# pse84 register map
Vendor: Cypress Semiconductor; Series: PSE84; File version: 1.0
CPU: CM33 r0p1, little endian, MPU, FPU, VTOR, 3 interrupt priority bits
Registers are 32-bit, read-write, reset 0x0 unless marked. A register's access mark holds for its fields unless they carry their own. Offsets are from the block's base; [hi:lo] are bit positions; lines under a group give offsets from that group; {n}, {i} and the like mark numbered series; 'fields as' and 'values as' point back to an identical list; <NAME> marks a mode.

## I3C — I3C controller top
Base 0x42A50000
0x00 CORE group — registers in I3C IP core
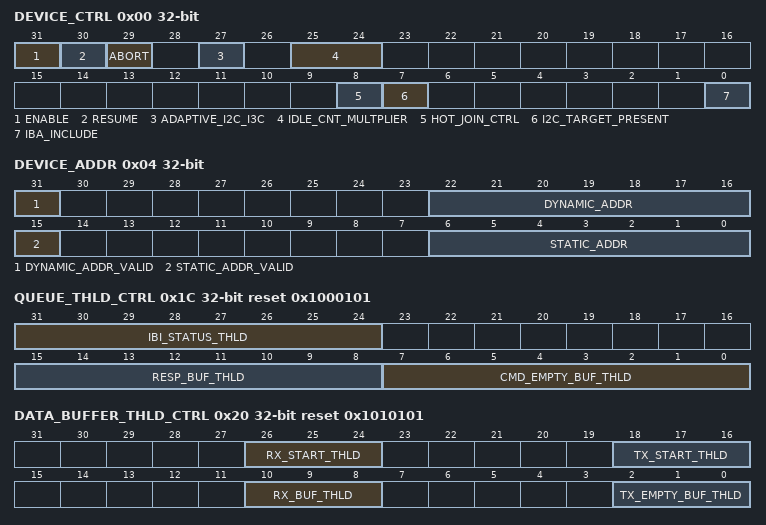
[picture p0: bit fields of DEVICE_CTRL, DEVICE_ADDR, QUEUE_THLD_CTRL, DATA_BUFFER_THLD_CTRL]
  0x00 DEVICE_CTRL — Device Control Register
    [31] ENABLE — I3C Enable Controls whether or not I3C functionality is enabled. When functioning as the Active Controller, software can write to this register to request to disable the I3C block. However, the block may not get disabled immediately and is 'Disabled' after commands in the Command queue (if any) are executed leading to a STOP condition on the bus and Controller FSM is in IDLE state (as indicated by PRESENT_STATE Register). When functioning as a Target, software can write to this register to request to disable the I3C block. However, the disable happens after the ongoing transfer is completed on the I3C bus. Software can read back 1'b0 from this field once disabling of I3C is completed. After power on reset, the software can enable I3C Secondary Controller or Target functionality by programming this bit to 1'b1. However the I3C bus interface of the block will respond to transfer on the bus, only after it observes Bus Available condition for BUS_AVAILABLE_TIME*IDLE_CNT_MULTPLIER counts of pclk period. The successful completion of Enable/Disable of the block depends on availability of SCL to the controller at the time of performing this operation, and hence may not happen instantly. Values: 0x0: Disables the I3C controller. 0x1: Enables the I3C controller.
    [30] RESUME — I3C Resume This bit is used to resume the I3C block after it goes to the Halt state. When functioning as the Active Controller, the block goes to the halt state (as indicated in PRESENT_STATE Register) due to any type of error in the transfer (the type of error is indicated by ERR_STATUS field in the RESPONSE_QUEUE_PORT register). After the block goes to the Halt state, the application has to write 1'b1 to this bit to resume. This bit is auto-cleared once the block resumes the transfers by initiating the next command. When functioning as a Target, the block goes to the halt state due to following conditions: 1 => Any type of error in the transfer (the type of error is indicated by ERR_STATUS field in the RESPONSE_QUEUE_PORT register) 2 => MRL Register updated by the Active Controller through SETMRL CCC. After the device has gone to halt state, the application has to take necessary action to handle the error condition and then write 1'b1 to this bit to resume the controller. This bit is auto-cleared once the controller is ready to accept new transfers.
    [29] ABORT — I3C Abort. This bit is only valid when this I3C Device is functioning as the Active Controller. This bit allows this device to relinquish the I3C Bus before completing the issued transfer. In response to an ABORT request, the Controller issues the STOP condition after the complete data byte is transferred or received. This bit is auto-cleared once the transfer is aborted and the controller issues a 'Transfer Abort' interrupt.
    [27] ADAPTIVE_I2C_I3C — Hot-Join Control for Adaptive I2C/I3C Mode This bit is only valid when this I3C Device is functioning as a Target and I3C_MODE_I2C.MODE_I2C is set to 0 (Adaptive I2C/I3C Mode). In Adaptive Mode, this bit is used to enable some features of this target device. This bit is cleared automatically if the controller determines the mode as I3C. Values: 0x0: The device initiates a Hot-Join without determining the bus mode and assuming itself to be on I3C bus. 0x1: The device initiates a Hot-Join request only after it has switched to I3C mode of operation.
    [25:24] IDLE_CNT_MULTPLIER — Idle count multiplier. This bit is only valid when this I3C Device is functioning as a Target. After power-on reset, this Target is enabled only after it sees both SDA and SCL lines idle for a specified time. This idle time is calculated by multipliying IDLE_CNT_MULTPLIER with BUS_AVAILABLE_TIME field in the BUS_FREE_AVAIL_TIMING register. Values: 0x00: BUS_AVAILABLE_TIME * 1 0x01: BUS_AVAILABLE_TIME * 2 0x10: BUS_AVAILABLE_TIME * 4 0x11: BUS_AVAILABLE_TIME * 8
    [8] HOT_JOIN_CTRL — Hot-Join ACK/NACK Control This bit is only valid when this I3C Device is functioning as the Active Controller. This bit acts as a global control to ACK/NACK the Hot-Join request from the devices. The Active Controller ACK/NACKs the Hot-Join request from other devices connected on the I3C Bus, based on programming of this bit. Values: 0x0: ACK the Hot-Join request. 0x1: NACK and send broadcast CCC(auto-disable) to disable Hot-join.
    [7] I2C_TARGET_PRESENT — I2C Target Present This bit is only valid when this I3C Device is functioning as the Active Controller. This bit indicates whether any Legacy I2C devices are present in the bus. In HDR mode, this field is used to select TSL over TSP in a mixed bus configuration. Values: 0x0 (DISABLED): I2C Target not present 0x1 (ENABLED): I2C Target present
    [0] IBA_INCLUDE — I3C Broadcast Address Include. This bit is only valid when this I3C Device is functioning as the Active Controller. This bit is used to include the I3C broadcast address (0x7E) in private transfers. Note: If the I3C broadcast address is not included in private transfers, In-band Interrupts (IBI) driven from Targets might not win address arbitration and IBIs will get delayed. Values: 0x0: I3C Broadcast Address is not included in Private Transfers 0x1: I3C Broadcast Address is included in Private Transfers
  0x04 DEVICE_ADDR — Device Address Register
    [31] DYNAMIC_ADDR_VALID — Dynamic Address Valid This bit is used to control whether the DYNAMIC_ADDR is valid or not. =>When functioning as the Primary Controller, the user/application must set this bit to 1 along with the DYNAMIC_ADDR. =>When functioning as a Target, the block sets this bit to 1 when the Active Controller assigns the Dynamic address during ENTDAA or SETDASA mechanism. + Values: 0x0: Dynamic Address is invalid 0x1: Dynamic Address is valid
    [22:16] DYNAMIC_ADDR — Device Dynamic Address. This field is used to program the Device Dynamic Address. The block uses this address for I3C transfers. => When functioning as the Primary Controller, the user/application must program the Dynamic Address. => When functioning as a Target, the Active Controller assigns this address during ENTDAA or SETDASA procedures.
    [15] STATIC_ADDR_VALID — Static Address Valid. This field is only valid when this I3C Device is functioning as a Target. Values: 0x0: Static Address in STATIC_ADDR field is invalid 0x1: Static Address in STATIC_ADDR field is valid
    [6:0] STATIC_ADDR — Device Static Address. This field is only valid when this I3C Device is functioning as a Target. The device uses this address to respond to SETDASA CCC Command to get the Dynamic Address if static address is valid (STATIC_ADDRESS_VALID must be set to 1).
  0x0C COMMAND_QUEUE_PORT wo reset not defined
    [31:0] COMMAND — 32-bit Command
  0x10 RESPONSE_QUEUE_PORT ro
    [31:0] RESPONSE — 32-bit Response
  0x14 TX_RX_DATA_PORT — Transmit/Receive Data Port Register
    [31:0] DATA_PORT — Transmit Data Port for write access and Receive Data Port for read access. This field is mapped to the TX Data Buffer when writing and to the RX Data Buffer when reading. The data is always packed in 4-byte aligned data words. If the command length is not aligned to the 4-bytes, then the additional data bytes have to be ignored.
  0x18 IBI_QUEUE_DATA ro — In-Band Interrupt Queue Data Register
    [31:0] IBI_DATA — In-Band Interrupt Data This register is mapped to the IBI Queue. The IBI Data is always packed in 4-byte aligned and put to the IBI Queue. If the incoming data is not aligned to the 4-bytes, then there are unused bytes in the end location of the IBI transfer.
  0x1C QUEUE_THLD_CTRL reset 0x1000101 — Queue Threshold Control Register
    [31:24] IBI_STATUS_THLD — In-Band Interrupt Status Threshold Value. This field controls the number of IBI status entries (or greater) in the IBI queue that trigger the IBI_THLD_STAT interrupt. Every In Band Interrupt received (with or without Payload) by the block generates an IBI status. The valid range is 0 to IC_IBI_BUF_DEPTH-1. The application should program only valid values. NOTE: The valid value is only 0 if IBI with payload is selected in the configuration. Values: 0x0 <= N < IC_RESP_BUF_DEPTH: Interrupt will trigger when queue has N+1 valid entries. Each IBI status entry can represent the complete (IBI payload byte size <= 4*IBI_DATA_THLD) IBI payload or a segment (IBI payload byte size > 4*IBI_DATA_THLD) of the IBI payload.
    [15:8] RESP_BUF_THLD — Response Buffer Threshold Value. Controls the minimum number of valid entries in the Response Queue that trigger the RESP_READY_STAT_INTR interrupt. The valid range is 0 to IC_RESP_BUF_DEPTH-1. The application should program only valid values. Values: 0x0 <= N < IC_RESP_BUF_DEPTH: Interrupt will trigger when queue has N+1 valid entries.
    [7:0] CMD_EMPTY_BUF_THLD — Command Buffer Empty Threshold Value Controls the minimum number of empty locations in the Command Queue that trigger the CMD_QUEUE_READY_STAT interrupt. The valid range is 0 to IC_CMD_BUF_DEPTH-1. The application should program only valid values. Values: 0x0: Interrupt will trigger when the queue is completely empty 0x0 < N < 16: Interrupt will trigger when queue has N empty locations.
  0x20 DATA_BUFFER_THLD_CTRL reset 0x1010101 — Data Buffer Threshold Control Register
    [26:24] RX_START_THLD — Receive Start Threshold Value. When functioning as the Active Controller, when the controller is set up to initiate a read transfer, it waits until either one of the conditions are met before it initiates the read transfer on the I3C Interface. => Data length (as specified in the command) number of locations are empty in the Receive FIFO. => Threshold number of locations (or more) are empty in the Receive FIFO. When functioning as a Target, the block ACKs a write request from the Active Controller only if threshold number of empty locations(or more) are available in its receive buffer. The supported values for RX_START_THLD are: 0x0: Threshold of at least 1 empty entry 0x1: Threshold of at least 4 empty entries 0x2: Threshold of at least 8 empty entries 0x3: Threshold of at least 16 empty entries 0x4: Threshold of at least 32 empty entries 0x5: Threshold of at least 64 empty entries
    [18:16] TX_START_THLD — Transfer Start Threshold Value. When functioning as the Active Controller, when the Controller is set up to initiate a write transfer, it waits until either one of the following conditions are met before it initiates the write transfer on the I3C Interface. => Data length (as specified in the command) number of locations are filled in the TX FIFO. => Threshold number of entries (or more) are available in the TX FIFO When functioning as a Target, the Target ACKs a read request from the Active Controller only if either one of the following conditions are met. => Data length (as specified in the command) number of locations are filled in the Transmit FIFO => Threshold number of entries (or more) are available in the Transmit FIFO Supported values: 0x0: Threshold of at least 1 valid entry 0x1: Threshold of at least 4 valid entries 0x2: Threshold of at least 8 valid entries 0x3: Threshold of at least 16 valid entries 0x4: Threshold of at least 32 valid entries 0x5: Threshold of at least 64 valid entries
    [10:8] RX_BUF_THLD — Receive Buffer Threshold Value. This field controls the number of valid entries (or above) in the RX FIFO that trigger the RX_THLD_STAT interrupt. If the programmed value is greater than the buffer depth, then threshold is set to IC_RX_BUF_DEPTH. Supported values: 0x0: Interrupt triggers with at least 1 valid entry 0x1: Interrupt triggers with at least 4 valid entries 0x2: Interrupt triggers with at least 8 valid entries 0x3: Interrupt triggers with at least 16 valid entries 0x4: Interrupt triggers with at least 32 valid entries 0x5: Interrupt triggers with at least 64 valid entries
    [2:0] TX_EMPTY_BUF_THLD — Transmit Buffer Empty Threshold Value This field controls the number of empty locations (or above) in the TX FIFO that trigger the TX_THLD_STAT interrupt. If the programmed value is greater than the buffer depth, then threshold is set to IC_TX_BUF_DEPTH. Supported values: 0x0: Interrupt triggers with at least 1 empty entry 0x1: Interrupt triggers with at least 4 empty entries 0x2: Interrupt triggers with at least 8 empty entries 0x3: Interrupt triggers with at least 16 empty entries 0x4: Interrupt triggers with at least 32 empty entries 0x5: Interrupt triggers with at least 64 empty entries
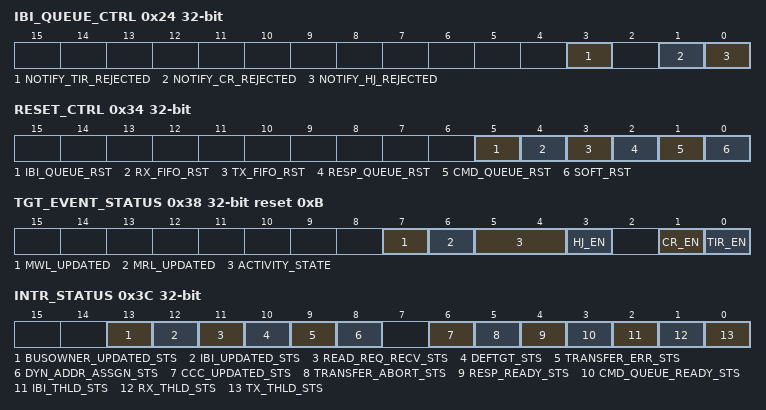
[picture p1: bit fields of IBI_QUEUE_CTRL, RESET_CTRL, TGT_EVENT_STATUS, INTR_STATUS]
  0x24 IBI_QUEUE_CTRL — IBI Queue Control Register
    [3] NOTIFY_TIR_REJECTED — Notify Rejected Target Interrupt Request Control. This bit is only valid when this I3C Device is functioning the Active Controller, and is used to suppress reporting to the application about rejected Target Interrupt Request. Values: 0x0: Disables passing the IBI Status to the IBI FIFO (hence not notifying the application) when a Target Interrupt Request is NACKed and auto-disabled based on the IBI_SIR_REQ_REJECT Register. 0x1: Enables writing the IBI Status to the IBI FIFO (hence notifying the application) when a Target Interrupt Request is NACKed and auto-disabled based on the IBI_SIR_REQ_REJECT Register.
    [1] NOTIFY_CR_REJECTED — Notify Rejected Controller Role Request (CR) Control. This bit is only valid when this I3C Device is functioning the Active Controller, and is used to suppress reporting to the application about Controller Role Request (CR) rejected. Values: 0x0: Disable passing the IBI Status to the IBI FIFO (hence not notifying the application) when a CR Request is NACKed and auto-disabled based on the IBI_CR_REQ_REJECT Register. 0x1: Enable writing the IBI Status to the IBI FIFO (hence notifying the application) when a CR Request is NACKed and auto-disabled based on the IBI_CR_REQ_REJECT Register.
    [0] NOTIFY_HJ_REJECTED — Notify Rejected Hot-Join Control. This bit is only valid when this I3C Device is functioning the Active Controller, and is used to suppress reporting to the application about Hot-Join request rejected (NACK and Auto Disable). Values: 0x0: Disable passing the IBI Status to the IBI FIFO (hence not notifying the application) when a HJ Request is NACKed and auto-disabled based on the DEVICE_CTRL.HOT_JOIN_CTRL. 0x1: Enable writing the IBI Status to the IBI FIFO (hence notifying the application) when a HJ Request is NACKed and auto-disabled based on the DEVICE_CTRL.HOT_JOIN_CTRL.
  0x2C IBI_CR_REQ_REJECT — IBI CR Request Rejection Control Register
    [31:0] CR_REQ_REJECT — Controller Role Request Reject. This field determines how the block responds to incoming Controller Role Requests from other Secondary Controller devices. The responses possible are: => ACK request to become Active Controller => NACK and send Directed DISEC CCC (with DISCR bit set) to disable the interrupting Controller. A device specific policy can be established by appropriately programming this register.
  0x30 IBI_TIR_REQ_REJECT — IBI TIR Request Rejection Control Register
    [31:0] SIR_REQ_REJECT — In-band Target Interrupt Request Reject. This field determines how the block responds to incoming Target Interrupt Requests from other Target devices. The responses possible are: => ACK request to become Active Controller => NACK and send Directed DISEC CCC (with DISINT bit set) to disable the interrupting Controller. A device specific policy can be established by appropriately programming this register.
  0x34 RESET_CTRL — Reset Control Register
    [5] IBI_QUEUE_RST — IBI Queue Software Reset. This bit is only valid when functioning as the Active Controller. Write 0x1 to this bit to exercise IBI Queue reset. This bit is cleared automatically once the IBI Queue reset is completed. Before the reset is completed, write accesses and read accesses to the other registers will return a bus error.
    [4] RX_FIFO_RST — Receive Buffer Software Reset. Write 0x1 to this bit to exercise Receive Buffer reset This bit is cleared automatically once the Receive buffer reset is completed. Before the reset is completed, write accesses and read accesses to the other registers will return a bus error.
    [3] TX_FIFO_RST — Transmit Buffer Software Reset. Write 0x1 to this bit to exercise Transmit Buffer reset. This bit is cleared automatically once the Transmit Buffer reset is completed. Before the reset is completed, write accesses and read accesses to the other registers will return a bus error.
    [2] RESP_QUEUE_RST — Response Queue Software Reset. Write 1'b1 to this bit to exercise Response Queue reset. This bit is cleared automatically once the Response Queue reset is completed. Before the reset is completed, write accesses and read accesses to the other registers will return a bus error.
    [1] CMD_QUEUE_RST — Command Queue Software Reset. Write 0x1 to this bit to exercise Command Queue reset. This bit is cleared automatically once the Command Queue reset is completed. Before the reset is completed, write accesses and read accesses to the other registers will return a bus error.
    [0] SOFT_RST — Core Software Reset. Write 1'b1 to this bit to exercise software reset. This resets all Buffers - Receive, Transmit, Command, and Response. This bit is cleared automatically once the core reset is completed. Before the reset is completed, write accesses and read accesses to the other registers will return a bus error. To finish the reset, it can take up to (15*Tpclk + 22*Tcore_clk) in worst case. (below reset cases are similar).
  0x38 TGT_EVENT_STATUS reset 0xB — Target Event Status Register
    [7] MWL_UPDATED — MWL Updated Status. This bit indicates a SETMWL CCC is received by the Target. The updated MWL value can be read from TGT_MAX_LEN register. This status can be cleared by writing 0x1 to this field after reading the updated MWL.
    [6] MRL_UPDATED — MRL Updated Status. This bit indicates a SETMRL CCC is received by the Target. The updated MRL value can be read from TGT_MAX_LEN register. This status can be cleared by writing 0x1 to this field after reading the updated MRL.
    [5:4] ACTIVITY_STATE ro — Activity State Status This bit reflects the Activity State of this Target set by the Active Controller. Values: 0x0: ENTAS0 0x1: ENTAS1 0x2: ENTAS2 0x3: ENTAS3
    [3] HJ_EN — Hot-Join Interrupt Enable. This bit is only valid when this I3C Device is functioning as a Target, and reflects whether the Hot-Join Request Interrupts are allowed on the I3C bus or not. The Target application can choose to Disable HJ Capability of the Target controller (if selected) by setting this field to 0 before 'Enabling' the block. When done so, the Target will not initiate Hot Join and will take part in Address Assignment without initiating Hot Join. If this field is NOT set to 0 by the Target application, it can be set or cleared by the I3C Controller via ENEC or DISEC CCCs. Once Disabled by software, CCCs do not have any effect on this field.
    [1] CR_EN ro — Controller Role Request (CR) Enable. This bit is only valid when this I3C Device is functioning as a Target, and reflects whether the controller can initiate the Controller Role Request (CR) on the I3C bus or not. Usually, this bit is set or cleared by the Active Controller through ENEC or DISEC CCC.
    [0] TIR_EN ro — Target Interrupt Request Enable. This bit is only valid when this I3C Device is functioning as a Target, and reflects whether the block can initiate the SIR on the I3C bus or not. Usually, this bit is set or cleared by the Active Controller through ENEC or DISEC CCC.
  0x3C INTR_STATUS — Interrupt Status Register
    [13] BUSOWNER_UPDATED_STS — This interrupt is set when the block changes from being the Active Controller to a Secondary Controller/Target or vice versa. This bit can be cleared by writing 0x1.
    [12] IBI_UPDATED_STS — IBI status is updated. This field is used only When functioning as a Target. It indicates that the IBI request initiated through SIR request register is addressed and status is updated.
    [11] READ_REQ_RECV_STS — Read Request Received. This field is used only when functioning as a Target. Read Request received from the Active Controller when CMDQ is empty. This bit can be cleared by writing 0x1.
    [10] DEFTGT_STS — Define Target CCC Received Status. This interrupt is generated if DEFTGTS CCC is received. This bit can be cleared by writing 0x1.
    [9] TRANSFER_ERR_STS — Transfer Error Status. This interrupt is generated if any error occurs during transfer. The error type is specified in the response packet associated with the command (in ERR_STATUS field of RESPONSE_QUEUE_PORT register). This bit can be cleared by writing 0x1.
    [8] DYN_ADDR_ASSGN_STS — Dynamic Address Assigned Status. This field is used only When functioning as a Target,. This interrupt is generated if the device's Dynamic Address is assigned through SETDASA or ENTDAA CCC. This bit can be cleared by writing 0x1.
    [6] CCC_UPDATED_STS — CCC Table Updated Status. This field is used only when functioning as a Target. This interrupt is generated if any of the CCC registers are updated by the I3C Controller through CCC commands. This interrupt can be cleared by writing 0x1.
    [5] TRANSFER_ABORT_STS — Transfer Abort Status. This field is used only when functioning as the Active Controller,. This interrupt is generated if the transfer is aborted. This interrupt can be cleared by writing 0x1.
    [4] RESP_READY_STS ro — Response Queue Ready Status. This interrupt is generated when number of entries in the response queue is greater than or equal to the threshold value specified by the RESP_BUF_THLD field in the QUEUE_THLD_CTRL register. This interrupt is cleared automatically when the number of entries in the response buffer is less than the threshold value specified.
    [3] CMD_QUEUE_READY_STS ro — Command Queue Ready. This interrupt is generated when number of empty locations in the command queue is greater than or equal to the threshold value specified by the CMD_EMPTY_BUF_THLD field in the QUEUE_THLD_CTRL register. This interrupt is cleared automatically when the number of empty locations in the command buffer is less than the threshold value specified.
    [2] IBI_THLD_STS ro — IBI Buffer Threshold Status. This field is only used when the block is functioning as the Active Controller. This interrupt is generated when the number of entries in the IBI buffer is greater than or equal to the threshold value specified by the IBI_BUF_THLD field in the QUEUE_THLD_CTRL register. This interrupt is cleared automatically when the number of entries in IBI buffer is less than the threshold value specified.
    [1] RX_THLD_STS ro — Receive Buffer Threshold Status. This interrupt is generated when number of entries in the receive buffer is greater than or equal to threshold value specified by the RX_BUF_THLD field in the DATA_BUFFER_THLD_CTRL register. This interrupt is cleared automatically when the number of entries in receive buffer is less than the threshold value specified.
    [0] TX_THLD_STS ro — Transmit Buffer Threshold Status. This interrupt is generated when the number of empty locations in the transmit buffer is greater than or equal to the threshold value specified by the TX_EMPTY_BUF_THLD field in the DATA_BUFFER_THLD_CTRL register. This interrupt is cleared automatically when the number of empty locations in transmit buffer is less than threshold value specified.
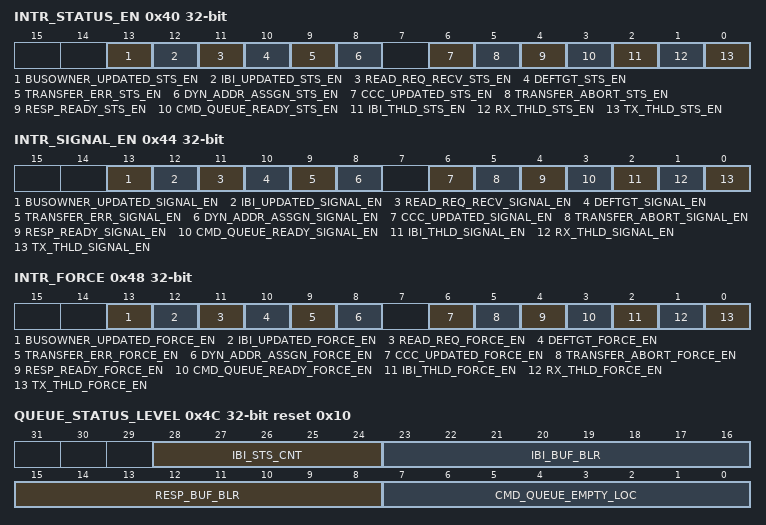
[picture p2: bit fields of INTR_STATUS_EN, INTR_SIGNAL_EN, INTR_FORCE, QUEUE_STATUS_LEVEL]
  0x40 INTR_STATUS_EN — Interrupt Status Enable Register.
    [13] BUSOWNER_UPDATED_STS_EN — Bus owner Updated Status Enable
    [12] IBI_UPDATED_STS_EN — IBI Updated Status Enable This field is only valid when functioning as a Target.
    [11] READ_REQ_RECV_STS_EN — Read Request Received Status Enable This field is only valid when functioning as a Target.
    [10] DEFTGT_STS_EN — Define Target CCC Received Status Enable
    [9] TRANSFER_ERR_STS_EN — Transfer Error Status Enable
    [8] DYN_ADDR_ASSGN_STS_EN — Dynamic Address Assigned Status Enable This field is only valid when functioning as a Target.
    [6] CCC_UPDATED_STS_EN — CCC Table Updated Status Enable. This field is only valid when functioning as a Target.
    [5] TRANSFER_ABORT_STS_EN — Transfer Abort Status Enable. This field is only valid when functioning as the Active Controller.
    [4] RESP_READY_STS_EN — Response Queue Ready Status Enable
    [3] CMD_QUEUE_READY_STS_EN — Command Queue Ready Status Enable
    [2] IBI_THLD_STS_EN — IBI Buffer Threshold Status Enable This field is only valid when functioning aa the Active Controller.
    [1] RX_THLD_STS_EN — Receive Buffer Threshold Status Enable
    [0] TX_THLD_STS_EN — Transmit Buffer Threshold Status Enable
  0x44 INTR_SIGNAL_EN — Interrupt Signal Enable Register
    [13] BUSOWNER_UPDATED_SIGNAL_EN — Bus owner Updated Signal Enable
    [12] IBI_UPDATED_SIGNAL_EN — IBI Updated Signal Enable This field is only valid when functioning as a Target.
    [11] READ_REQ_RECV_SIGNAL_EN — Read Request Received Signal Enable This field is only valid when functioning as a Target.
    [10] DEFTGT_SIGNAL_EN — Define Target CCC Received Signal Enable
    [9] TRANSFER_ERR_SIGNAL_EN — Transfer Error Signal Enable
    [8] DYN_ADDR_ASSGN_SIGNAL_EN — Dynamic Address Assigned Signal Enable This field is only valid when functioning as a Target.
    [6] CCC_UPDATED_SIGNAL_EN — CCC Table Updated Signal Enable. This field is only valid when functioning as a Target.
    [5] TRANSFER_ABORT_SIGNAL_EN — Transfer Abort Signal Enable. This field is only valid when functioning as the Active Controller.
    [4] RESP_READY_SIGNAL_EN — Response Queue Ready Signal Enable
    [3] CMD_QUEUE_READY_SIGNAL_EN — Command Queue Ready Signal Enable
    [2] IBI_THLD_SIGNAL_EN — IBI Buffer Threshold Signal Enable This field is only valid when functioning aa the Active Controller.
    [1] RX_THLD_SIGNAL_EN — Receive Buffer Threshold Signal Enable
    [0] TX_THLD_SIGNAL_EN — Transmit Buffer Threshold Signal Enable
  0x48 INTR_FORCE wo — Interrupt Force Enable Register
    [13] BUSOWNER_UPDATED_FORCE_EN — Bus owner Updated Force Enable
    [12] IBI_UPDATED_FORCE_EN — IBI Updated Force Enable This field is only valid when functioning as a Target.
    [11] READ_REQ_FORCE_EN — Read Request Received Force Enable This field is only valid when functioning as a Target.
    [10] DEFTGT_FORCE_EN — Define Target CCC Received Force Enable
    [9] TRANSFER_ERR_FORCE_EN — Transfer Error Force Enable
    [8] DYN_ADDR_ASSGN_FORCE_EN — Dynamic Address Assigned Force Enable This field is only valid when functioning as a Target.
    [6] CCC_UPDATED_FORCE_EN — CCC Table Updated Force Enable. This field is only valid when functioning as a Target.
    [5] TRANSFER_ABORT_FORCE_EN — Transfer Abort Force Enable. This field is only valid when functioning as the Active Controller.
    [4] RESP_READY_FORCE_EN — Response Queue Ready Force Enable
    [3] CMD_QUEUE_READY_FORCE_EN — Command Queue Ready Force Enable
    [2] IBI_THLD_FORCE_EN — IBI Buffer Threshold Force Enable This field is only valid when functioning aa the Active Controller.
    [1] RX_THLD_FORCE_EN — Receive Buffer Threshold Force Enable
    [0] TX_THLD_FORCE_EN — Transmit Buffer Threshold Force Enable
  0x4C QUEUE_STATUS_LEVEL ro reset 0x10
    [28:24] IBI_STS_CNT
    [23:16] IBI_BUF_BLR — IBI Buffer Level Value. This field is used when functioning as the Active Controller. When IC_HAS_IBI_DATA = 0, contains ontains the number of Valid IBI Status entries in the IBI Buffer. When IC_HAS_IBI_DATA = 1, contains the number of valid IBI Data entries in the IBI Data Buffer.
    [15:8] RESP_BUF_BLR — Response Buffer Level Value. Contains the number of valid data entries in the response Buffer.
    [7:0] CMD_QUEUE_EMPTY_LOC — Command Queue Empty Locations. Contains the number of empty locations in the command Buffer.
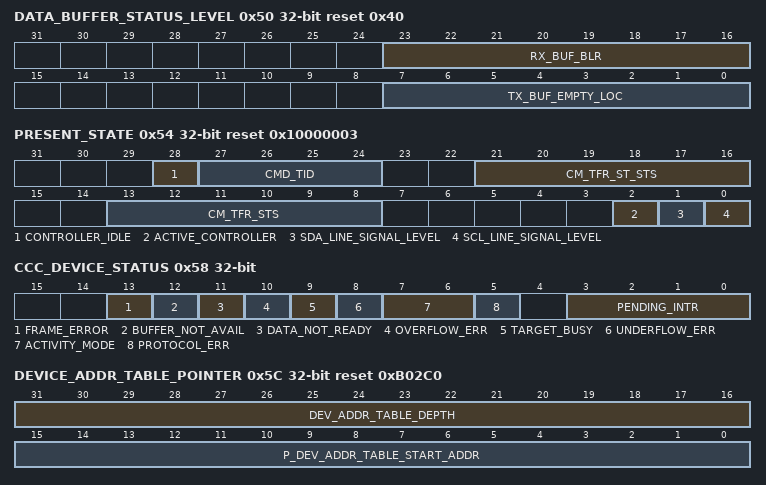
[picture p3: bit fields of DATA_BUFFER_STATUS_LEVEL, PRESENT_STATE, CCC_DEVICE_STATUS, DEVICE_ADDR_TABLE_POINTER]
  0x50 DATA_BUFFER_STATUS_LEVEL ro reset 0x40
    [23:16] RX_BUF_BLR — Receive Buffer Level Value. Contains the number of valid data entries in the receive Buffer.
    [7:0] TX_BUF_EMPTY_LOC — Transmit Buffer Empty Level Value. Contains the number of empty locations in the transmit Buffer.
  0x54 PRESENT_STATE ro reset 0x10000003
    [28] CONTROLLER_IDLE — This bit is only valid when this I3C Device is functioning the Active Controller, and reflects whether the block is in the Idle state or not. This bit is set when all the Queues (Command , Response, IBI) and Buffers (Transmit and Receive) are empty and the Controller State machine is in Idle state. Values: 0x0 Controller is not in IDLE State 0x1 Controller is in IDLE State.
    [27:24] CMD_TID — This field reflects the Transaction-ID of the current executing command.
    [21:16] CM_TFR_ST_STS — Active Controller Transfer State Status. This bit is only valid when this I3C Device is functioning the Active Controller, and indicates the state of current transfer currently executing by the I3C block. Values: 0x0: IDLE (Controller is Idle state, waiting for commands from application or Target initated In-band Interrupt) 0x1: START Generation State. 0x2: RESTART Generation State. 0x3: STOP Generation State. 0x4: START Hold Generation for the Target Initiated START State. 0x5: Broadcast Write Address Header(7'h7E,W) Generation State. 0x6: Broadcast Read Address Header(7'h7E,R) Generation State. 0x7: Dynamic Address Assignment State. 0x8: Target Address Generation State. 0xB: CCC Byte Generation State. 0xC: HDR Command Generation State. 0xD: Write Data Transfer State. 0xE: Read Data Transfer State. 0xF: In-Band Interrupt(SIR) Read Data State. 0x10: In-Band Interrupt Auto-Disable State 0x11: HDR-DDR CRC Data Generation/Receive State. 0x12: Clock Extension State. 0x13: Halt State.
    [13:8] CM_TFR_STS — Transfer Type Status. Indicates the type of transfer currently executing by the I3C block. When functioning as the Active Controller, possible values are: 0x0: IDLE (Block is in Idle state, waiting for commands from application or Target initated In-band Interrupt) 0x1: Broadcast CCC Write Transfer. 0x2: Directed CCC Write Transfer. 0x3: Directed CCC Read Transfer. 0x4: ENTDAA Address Assignment Transfer. 0x5: SETDASA Address Assignment Transfer. 0x6: Private I3C SDR Write Transfer. 0x7: Private I3C SDR Read Transfer. 0x8: Private I2C SDR Write Transfer. 0x9: Private I2C SDR Read Transfer. 0xA: Private HDR Ternary Symbol (TS) Write Transfer. 0xB: Private HDR Ternary Symbol (TS) Read Transfer. 0xC: Private HDR Double-Data Rate (DDR) Write Transfer. 0xD: Private HDR Double-Data Rate (DDR) Read Transfer. 0xE: Servicing In-Band Interrupt Transfer. 0xF: Halt state (Block is in Halt State, waiting for the application to resume through DEVICE_CTRL Register) When functioning as a Target, possible values are: 0x0: IDLE (Block is in Idle state) 0x1: Hot-Join transfer state 0x2: IBI transfer state 0x3: Controller write transfer ongoing 0x4: Read data prefetch state 0x5: Controller read transfer ongoing 0x6: Bock is controller in Halt State waiting for resume from application
    [2] ACTIVE_CONTROLLER — This Bit is used to check whether the block is currently the Active Controller or not. The Active Controller is the Controller that owns the SCL line. Values: 0x0: Secondary Controller is not the Active Controller and needs to request to be the Active Controller before initiating any transfer on the line. 0x1: Secondary Controller is the Active Controller and can initiate transfers on the line.
    [1] SDA_LINE_SIGNAL_LEVEL — This bit is only valid when this I3C Device is functioning the Active Controller, and is used for debug and error recovery. This bit reflects the value of the synchronized sda_in_a signal.
    [0] SCL_LINE_SIGNAL_LEVEL — This bit is only valid when this I3C Device is functioning the Active Controller, and is used for debug and error recovery. This bit reflects the value of the synchronized scl_in_a signal.
  0x58 CCC_DEVICE_STATUS ro — Device Operating Status Register.
    [13] FRAME_ERROR — Frame Error This bit is only valid when this I3C Device is functioning as a Target, and is set when a private write request initiated by the Active Controller has a frame error in HDR-DDR/HDR-TSP/TSL mode. This is cleared only after the Active Controller reads the device status through GETSTATUS_CCC.
    [12] BUFFER_NOT_AVAIL — Buffer not available This bit is only valid when this I3C Device is functioning as a Target, and is set when a private write request initiated by the Active Controller is NACKED because of RX buffer not having RX_BUF_THLD number of empty locations or Response buffer being full. In SDR mode of operation this is cleared when the Active Controller issues GETSTATUS CCC or upon space becoming available in the buffer and the successful completion of the next write transfer. In HDR mode of operation it is cleared only when the Active Controller issues GETSTATUS CCC.
    [11] DATA_NOT_READY — Data not ready This bit is only valid when this I3C Device is functioning as a Target, and is set when private a private read request initiated by the Active Controller is NACKED because of any of the following conditions Command FIFO Empty. Transmit FIFO threshold is not met. Response FIFO Full. This bit is cleared when the Active Controller issues GETSTATUS CCC or upon successful completion of the subsequent read transfer.
    [10] OVERFLOW_ERR — Overflow Error This bit is only valid when this I3C Device is functioning as a Target, and is set when an overflow error condition is detected during a private write transfer initiated by the Active Controller. This is cleared only after the Active Controller reads the Device Status through GETSTATUS CCC.
    [9] TARGET_BUSY — Target Busy This bit is set if any change is made by the Active Controller to the MRL register or occurance of any error. It is cleared after Target application resumes the block operation by writing to the RESUME bit of the DEVICE_CONTROL register.
    [8] UNDERFLOW_ERR — Underflow error This bit is only valid when this I3C Device is functioning as a Target, and is set when terminates a private read transfer initiated by the Active Controller is terminated by the device because of unavailability of data in the transmit buffer. This bit is cleared only after the Active Controller reads the Device Status through a GETSTATUS CCC.
    [7:6] ACTIVITY_MODE — Pending Interrupt This field reflects the value from I3C.CCC_GETSTATUS.ACT_MODE.
    [5] PROTOCOL_ERR — Protocol Error This bit is only valid when this I3C Device is functioning as a Target, and is set when a Parity/CRC error is encountered during a private write transfer initiated by the Active Controller.
    [3:0] PENDING_INTR — Pending Interrupt This field reflects the value from I3C.CCC_GETSTATUS.PENDING_INT.
  0x5C DEVICE_ADDR_TABLE_POINTER ro reset 0xB02C0 — Pointer for Device Address Table
    [31:16] DEV_ADDR_TABLE_DEPTH — Depth of the Device Address Table in the internal memory.
    [15:0] P_DEV_ADDR_TABLE_START_ADDR — Start Address of the Device Address Table in the internal memory.
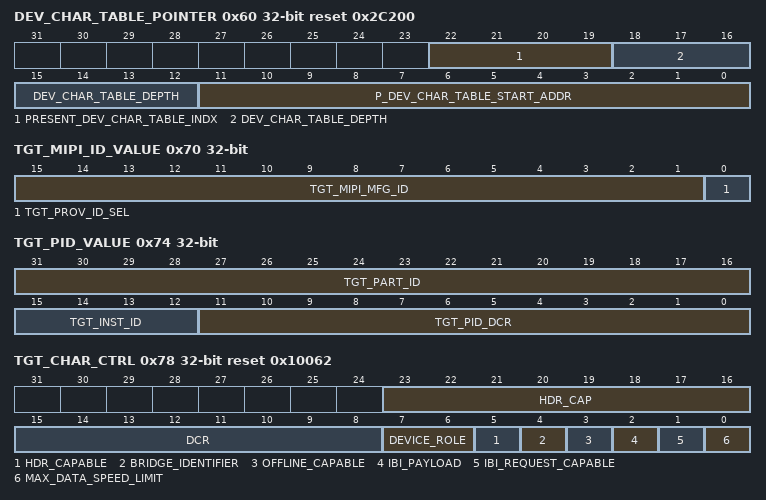
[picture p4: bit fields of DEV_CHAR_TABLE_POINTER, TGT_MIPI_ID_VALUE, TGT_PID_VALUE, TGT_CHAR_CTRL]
  0x60 DEV_CHAR_TABLE_POINTER reset 0x2C200 — Pointer for Device Characteristics Table
    [22:19] PRESENT_DEV_CHAR_TABLE_INDX — Current index of the Device Characteristics Table. This field returns the current location of Device Characteristics Table index. Initially, this index points to 0. Once the complete characteristics information of a Target device is written into Device Characteristics Table during ENTDAA, this index increments by 1. The first winning device information is stored in Device Characteristics Table index 0, the second winning device information in index 1, and so on. If required, this index can be used to override the location, where characteristic information of Target devices on the I3C bus are written during ENTDAA. Hence, this field is useful only when the device is functioning as the Active Controller. During DEFTGTS CCC, the index always starts from 0. When the device is functioning as a Target, this field is read-only.
    [18:12] DEV_CHAR_TABLE_DEPTH ro — Depth of Device Characteristics Table in the internal memory.
    [11:0] P_DEV_CHAR_TABLE_START_ADDR ro — Start Address of the Device Characteristics Table in the internal memory.
  0x6C VENDOR_SPECIFIC_REG_POINTER ro reset 0xB0 — Pointer for Vendor Specific Registers.
    [15:0] P_VENDOR_REG_START_ADDR — Start Address of Vendor specific registers.
  0x70 TGT_MIPI_ID_VALUE — I3C MIPI Manufacturer ID Register
    [15:1] TGT_MIPI_MFG_ID — Specifies the MIPI Manufacturer ID (Provisioned ID [47:33]).
    [0] TGT_PROV_ID_SEL — Specifies the Provisioned ID Type Selector (Provisioned ID [32]). Values: 0x0: Vendor Fixed Value 0x1: Random Value
  0x74 TGT_PID_VALUE — I3C Normal Provisional ID Register
    [31:16] TGT_PART_ID — Specifies the Part ID of this I3C block (PID[31:16]).
    [15:12] TGT_INST_ID — Specifies the MIPI Instance ID of this I3C block (Provisioned ID [15:12]).
    [11:0] TGT_PID_DCR — Specifies the last 12 bit of the MIPI Provisioned ID of this I3C block (Provisioned ID [11:0]).
  0x78 TGT_CHAR_CTRL reset 0x10062 — I3C Target Characteristic Register.
    [23:16] HDR_CAP ro
    [15:8] DCR — I3C Device Characteristic Regster (DCR) Value
    [7:6] DEVICE_ROLE — Device Role field in Bus Characteristic Register (BCR[7:6]). This field is set to 1 by default if configuration parameter IC_DEVICE_ROLE is set to 0x3 (Secondary Controller). The application is not expected to change the role once configured. But if the application chooses to operate the Secondary Controller (IC_DEVICE_ROLE==3) as 'Target Only' through programming, then the Device Role can be overwritten as Target (BCR[7:6] = 0x0). The field is Reset to its default value upon HW/SW Reset. SW must program the values again after issuing reset.
    [5] HDR_CAPABLE — SDR Only or SDR and HDR Capable field in Bus Characteristic Register (BCR[5]). This bit is set if any of the configuration parameter IC_SPEED_HDR_TS or IC_SPEED_HDR_DDR is set to 1. It is to be noted that the programming this field to 0 does not Disable the HDR Feature itself. This bit can be modified by the application if it does not want to advertise the Target's HDR capability to the Active Controller. The field is Reset to its default value upon HW/SW Reset. SW must program the values again after issuing reset.
    [4] BRIDGE_IDENTIFIER ro — Bridge Identifier field in Bus Characteristic Register (BCR[4]). This bit is set if configuration parameter IC_SLV_BRIDGE is set to 1.
    [3] OFFLINE_CAPABLE ro — Offline Capable field in Bus Characteristic Register (BCR[3]). This bit is set if configuration parameter IC_SLV_OFFLINE_CAP is set to 1.
    [2] IBI_PAYLOAD ro — IBI Payload field in Bus Characteristic Register (BCR[2]). This bit is set if configuration parameter IC_SLV_IBI_DATA is set to 1.
    [1] IBI_REQUEST_CAPABLE ro — IBI Request Capable field in Bus Characteristic Register (BCR[1]). This bit is set if configuration parameter IC_SLV_IBI is set to 1.
    [0] MAX_DATA_SPEED_LIMIT — Max Data Speed Limitation field in Bus Characteristic Register (BCR[0]). Specifies whether or not this I3C device has a maximum data speed limitation. If this bit is set to 0, controller NACK's the GETMXDS CCC sent by the Active Controller. If this bit is set to 1, controller returns the data in MAX_DATA_SPEED and MAX_READ_TURNAROUND register in response the GETMXDS CCC sent by the Active Controller. The field is reset to its default value upon HW/SW Reset. SW must program the values again after issuing reset.
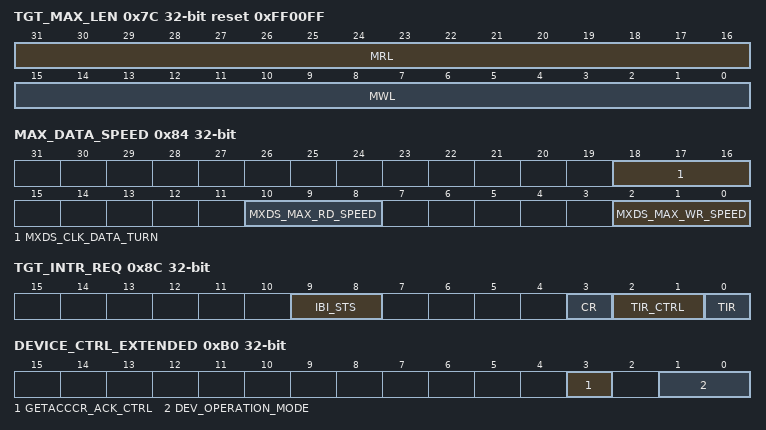
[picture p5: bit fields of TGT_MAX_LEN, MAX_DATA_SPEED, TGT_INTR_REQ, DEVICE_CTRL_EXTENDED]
  0x7C TGT_MAX_LEN ro reset 0xFF00FF — I3C Max Write/Read Length Register.
    [31:16] MRL — I3C Device Max Read Length
    [15:0] MWL — I3C Device Max Write Length
  0x80 MAX_READ_TURNAROUND ro — MXDS Maximum Read Turnaround Time.
    [23:0] MXDS_MAX_RD_TURN — Specifies the maximum read turnaround time (in microseconds (us)) of this I3C device.
  0x84 MAX_DATA_SPEED ro — Maximum Data Speed Register
    [18:16] MXDS_CLK_DATA_TURN, [10:8] MXDS_MAX_RD_SPEED, [2:0] MXDS_MAX_WR_SPEED
  0x8C TGT_INTR_REQ — Target Interrupt Request Register
    [9:8] IBI_STS ro
    [3] CR
    [2:1] TIR_CTRL
    [0] TIR — Target Interrupt Request When set, the Target Controller attempts to issue the SIR on the I3C bus. Once issued and when the Active Controller accepts (ACK), or if the block is unable to issue the SIR, then the block clears this bit automatically and updates the IBI_STS field. If the NACK response is received for the SIR, the block reattempts the SIR upon detecting the next START condition from the Active Controller or after the Bus Available Time. Once set, the application cannot clear this bit.
  0xB0 DEVICE_CTRL_EXTENDED — Device Control Extended Register
    [3] GETACCCR_ACK_CTRL — When functioning as a Target, this bit determines whether GETACCCR CCC from the Active Controller will be ACKed or NACKed. Values: 0x0: ACK the GETACCCR CCCs 0x1: NACK the GETACCCR CCCs
    [1:0] DEV_OPERATION_MODE — This bit is used to select the initial device role before the block is enabled. This field should only be written before the I3C block is enabled This field is automatically updated by the block once the a role change takes place. Values: 0x0: Primary Controller (starts as the Active Controller and initializes/configures the I3C bus) 0x1: Secondary Controller (starts as a Target, but can become the Active Controller)
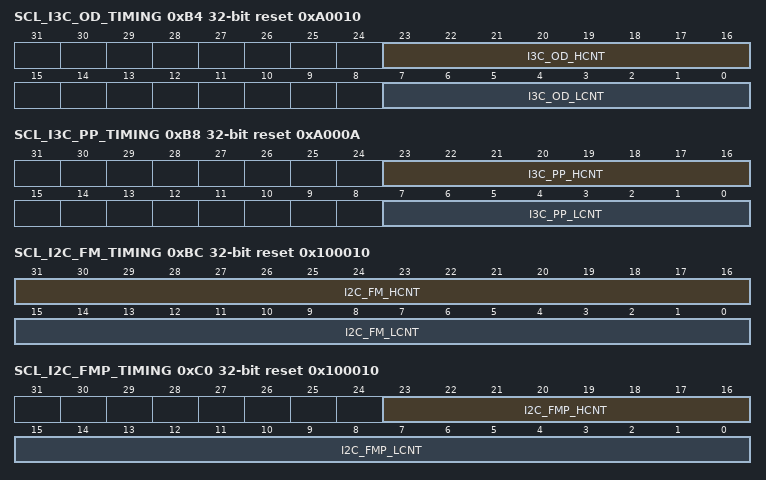
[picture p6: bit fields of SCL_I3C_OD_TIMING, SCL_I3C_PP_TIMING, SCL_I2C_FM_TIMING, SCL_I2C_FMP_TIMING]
  0xB4 SCL_I3C_OD_TIMING reset 0xA0010 — SCL I3C Open Drain Timing Register
    [23:16] I3C_OD_HCNT — I3C Open Drain High Count. SCL open-drain High count (I3C) for I3C transfers targeted to I3C devices.
    [7:0] I3C_OD_LCNT — I3C Open Drain Low Count. SCL Open-drain low count for I3C transfers targeted to I3C devices.
  0xB8 SCL_I3C_PP_TIMING reset 0xA000A — SCL I3C Push Pull Timing Register
    [23:16] I3C_PP_HCNT — I3C Push Pull High Count. SCL push-pull High count for I3C transfers targeted to I3C devices.
    [7:0] I3C_PP_LCNT — I3C Push Pull Low Count. SCL Push-pull low count for I3C transfers targeted to I3C devices.
  0xBC SCL_I2C_FM_TIMING reset 0x100010 — SCL I2C Fast Mode Timing Register
    [31:16] I2C_FM_HCNT — I2C Fast Mode High Count The SCL open-drain high count timing for I2C fast mode transfers.
    [15:0] I2C_FM_LCNT — I2C Fast Mode Low Count The SCL open-drain low count timing for I2C fast mode transfers.
  0xC0 SCL_I2C_FMP_TIMING reset 0x100010 — SCL I2C Fast Mode Plus Timing Register
    [23:16] I2C_FMP_HCNT — I2C Fast Mode Plus High Count The SCL open-drain high count timing for I2C fast mode plus transfers.
    [15:0] I2C_FMP_LCNT — I2C Fast Mode Plus Low Count The SCL open-drain low count timing for I2C fast mode plus transfers.
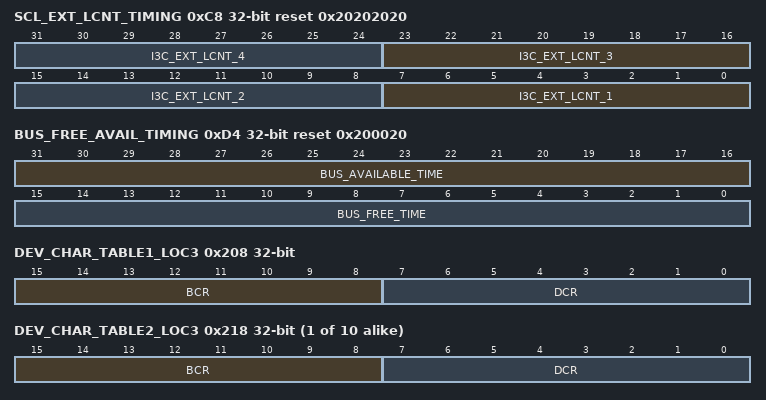
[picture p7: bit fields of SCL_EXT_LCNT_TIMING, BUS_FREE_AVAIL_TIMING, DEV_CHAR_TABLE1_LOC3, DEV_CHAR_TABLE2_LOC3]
  0xC8 SCL_EXT_LCNT_TIMING reset 0x20202020 — SCL Extended Low Count Timing Register.
    [8n-1:8n-8] I3C_EXT_LCNT_{n} (n=1..4) — I3C Extended Low Count Register {n} SDR{n} uses this register field for determining the extended SCL low phase.
  0xCC SCL_EXT_TERMN_LCNT_TIMING — SCL Termination Bit Low Count Timing Register
    [3:0] I3C_EXT_TERMN_LCNT — I3C Read Termination Bit Low count. Extended I3C Read Termination Bit low count for I3C Read transfers. Effective Termination-Bit Low Period is derived based on the SDR speed as shown below. SDR0 speed: I3C_PP_LCNT + I3C_EXT_TERMN_LCNT SDR1 speed: I3C_EXT_LCNT_1 + I3C_EXT_TERMN_LCNT SDR2 speed: I3C_EXT_LCNT_2 + I3C_EXT_TERMN_LCNT SDR3 speed: I3C_EXT_LCNT_3 + I3C_EXT_TERMN_LCNT SDR4 speed: I3C_EXT_LCNT_4 + I3C_EXT_TERMN_LCNT
  0xD0 SDA_HOLD_SWITCH_DLY_TIMING reset 0x10000 — SDA Hold and Mode Switch Delay Timing Register
    [18:16] SDA_TX_HOLD
  0xD4 BUS_FREE_AVAIL_TIMING reset 0x200020 — Bus Free and Available Timing Register
    [31:16] BUS_AVAILABLE_TIME — Bus Available Count Value This register field is used only When functioning as a Target. This field is used by the block to initiate an IBI after the STOP condition.
    [15:0] BUS_FREE_TIME — I3C Bus Free Count Value This register field is used only when functioning as the Active Controller. In a Pure Bus System, this field represents the tCAS parameter. In a Mixed Bus system, this field is expected to be programmed to tLOW of I2C Timing.
  0xD8 BUS_IDLE_TIMING reset 0x20
    [19:0] BUS_IDLE_TIME — Bus Idle Count Value This field is used by the block to initiate a Hot-Join request if the dynamic address is not valid.
  0x200 DEV_CHAR_TABLE1_LOC1 ro reset not defined — Device Characteristic Table Location-1 of Device1 , LSB_PROVISIONAL_ID
    [31:0] MSB_PROVISIONAL_ID — The 32 Most Significant Bits (MSBs) from the 48-bit MIPI Provisioned ID
  0x204 DEV_CHAR_TABLE1_LOC2 ro reset not defined — Device Characteristic Table Location-2 of Device1 , MSB_PROVISIONAL_ID
    [15:0] LSB_PROVISIONAL_ID — The 16 Least Significant Bits (LSBs) from the 48-bit MIPI Provisioned ID
  0x208 DEV_CHAR_TABLE1_LOC3 ro reset not defined — Device Characteristic Table Location-3 of Device1, BCR, DCR
    [15:8] BCR — Bus Characteristic Register (BCR)
    [7:0] DCR — Device Characteristic Register (DCR)
  0x20C DEV_CHAR_TABLE1_LOC4 ro reset not defined — Device Characteristic Table Location-4 of Device1, DEV_DYNAMIC_ADDR
    [7:0] DEV_DYNAMIC_ADDR1 — Dynamic Address assigned to the device.
  {0x1F0+0x10*j} DEV_CHAR_TABLE{j}_LOC1 ro reset not defined (j=2..11) — Device Characteristic Table Location-1 of Device{j}
    fields as CORE.DEV_CHAR_TABLE1_LOC1
  {0x1F4+0x10*j} DEV_CHAR_TABLE{j}_LOC2 ro reset not defined (j=2..11) — Device Characteristic Table Location-2 of Device{j}
    fields as CORE.DEV_CHAR_TABLE1_LOC2
  {0x1F8+0x10*j} DEV_CHAR_TABLE{j}_LOC3 ro reset not defined (j=2..11) — Device Characteristic Table Location-3 of Device{j}
    fields as CORE.DEV_CHAR_TABLE1_LOC3
  {0x1FC+0x10*j} DEV_CHAR_TABLE{j}_LOC4 ro reset not defined (j=2..11) — Device Characteristic Table Location-4 of Device{j}
    [7:0] DEV_DYNAMIC_ADDR{j} — Dynamic Address assigned to the device.
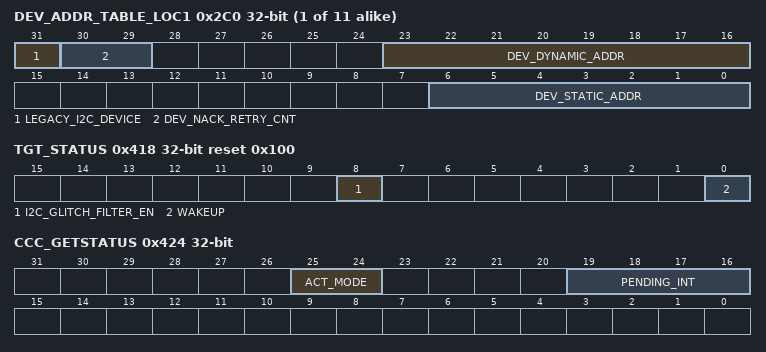
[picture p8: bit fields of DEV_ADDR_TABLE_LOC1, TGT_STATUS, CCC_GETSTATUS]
  {0x2BC+4j} DEV_ADDR_TABLE_LOC{j} reset not defined (j=1..11) — Device Address Table of Device{j}
    [31] LEGACY_I2C_DEVICE — Legacy I2C Device Values: 0x0: Device is a Legacy I2C Device 0x1: Device is an I3C Device
    [30:29] DEV_NACK_RETRY_CNT — This field is used to set the Device NACK Retry count for the particular device. If the Device NACKs for the device address, the block automatically retries the transfer until this count expires. If the Target NACKs for the mentioned number of retries, then the block generates an error response and moves to the Halt state. This feature is used for Retry Model for the following features mentioned in the I3C Specification: => Retry Model for Direct GET CCC Commands => The incoming SIR-IBI matches with the Target address initated by the Active Controller
    [23:16] DEV_DYNAMIC_ADDR — Device Dynamic Address with parity. This field consists of a Dynamic Address and a Parity Bit. The LSBs [22:16] consist of the Dynamic Address to be assigned for the winning I3C device when using ENTDAA command. The MSB [23] is the odd parity of the 7-bit Dynamic Address used for ENTDAA address assignment (~XOR(DEV_DYNAMIC_ADDR[22:16])
    [6:0] DEV_STATIC_ADDR — Device Static Address.
0x400 CTRL — I3C Block Control
  [31] ENABLED — IP Enable/Disable 0=IP is disabled/reset 1=IP is enabled/running when IP is disabled, write access to 3PIP area 'I3C_1_0_core' is ignored, read access to them get all zeros.
0x418 TGT_STATUS ro reset 0x100 — This register provides additional status information when functioning as a Target.
  [8] I2C_GLITCH_FILTER_EN — I2C 50ns glitch filter enable This bit is only valid when functioning as a Target.
  [0] WAKEUP — Target wakeup signal This field is only valid when functioning as a Target.
0x424 CCC_GETSTATUS — This register provides additional information on GETSTATUS CCCs received when functioning as a Target.
  [25:24] ACT_MODE — Target activity mode for GETSTATUS CCC This bit is only valid when functioning as a Target.
  [19:16] PENDING_INT — Pending interrupt info for GETSTATUS CCC This bit is only valid when functioning as a Target.
